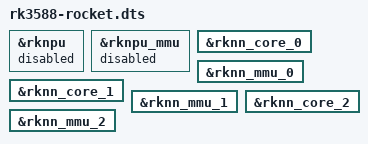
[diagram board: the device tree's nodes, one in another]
/dts-v1/;
/plugin/;

/ {
        fragment@0 {
                target = <&rknpu>;
                __overlay__ {
                        status = "disabled";
                };
        };

        fragment@1 {
                target = <&rknpu_mmu>;
                __overlay__ {
                        status = "disabled";
                };
        };

        fragment@2 {
                target = <&rknn_core_0>;
                __overlay__ {
                        status = "okay";
                };
        };

        fragment@3 {
                target = <&rknn_mmu_0>;
                __overlay__ {
                        status = "okay";
                };
        };

        fragment@4 {
                target = <&rknn_core_1>;
                __overlay__ {
                        status = "okay";
                };
        };

        fragment@5 {
                target = <&rknn_mmu_1>;
                __overlay__ {
                        status = "okay";
                };
        };

        fragment@6 {
                target = <&rknn_core_2>;
                __overlay__ {
                        status = "okay";
                };
        };

        fragment@7 {
                target = <&rknn_mmu_2>;
                __overlay__ {
                        status = "okay";
                };
        };
};
